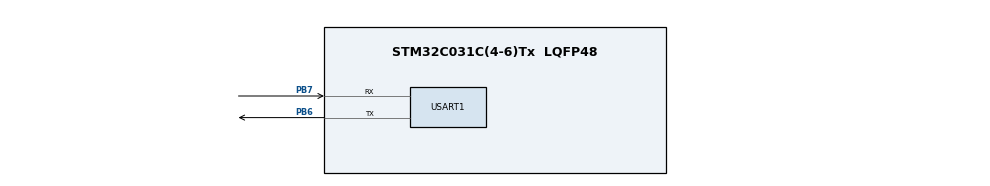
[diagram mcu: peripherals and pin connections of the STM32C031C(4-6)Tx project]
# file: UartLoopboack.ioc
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Mcu.Family=STM32C0
Mcu.Name=STM32C031C(4-6)Tx
Mcu.Package=LQFP48
PB6.Mode=Asynchronous
PB6.Signal=USART1_TX
PB7.Mode=Asynchronous
PB7.Signal=USART1_RX
ProjectManager.HeapSize=0x200
ProjectManager.StackSize=0x400
ProjectManager.TargetToolchain=STM32CubeIDE
RCC.ADCFreq_Value=12000000
RCC.AHBFreq_Value=12000000
RCC.CortexFreq_Value=12000000
RCC.EXTERNAL_CLOCK_VALUE=12288000
RCC.HCLKFreq_Value=12000000
RCC.HSE_VALUE=8000000
RCC.HSI_VALUE=48000000
RCC.LSE_VALUE=32768
RCC.SYSCLKFreq_VALUE=12000000
USART1.FIFOMode=FIFOMODE_ENABLE
USART1.VirtualMode-Asynchronous=VM_ASYNC
board=custom

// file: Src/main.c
/* USER CODE BEGIN Header */
/**
 ******************************************************************************
 * @file           : main.c
 * @brief          : Main program body
 ******************************************************************************
 * @attention
 *
 * Copyright (c) 2025 STMicroelectronics.
 * All rights reserved.
 *
 * This software is licensed under terms that can be found in the LICENSE file
 * in the root directory of this software component.
 * If no LICENSE file comes with this software, it is provided AS-IS.
 *
 ******************************************************************************
 */
/* USER CODE END Header */
#include "main.h"

/* USER CODE BEGIN Includes */
#include "byte_fifo.h"
/* USER CODE END Includes */

/* USER CODE BEGIN PM */
#define BUFFER_SIZE 256
/* USER CODE END PM */

UART_HandleTypeDef huart1;

/* USER CODE BEGIN PV */
static uint8_t fifo_data[BUFFER_SIZE];
static struct byte_fifo_t fifo =
    {
        .data = fifo_data,
        .size = BUFFER_SIZE,
};
/* USER CODE END PV */

void SystemClock_Config(void);
static void MX_GPIO_Init(void);
static void MX_USART1_UART_Init(void);

int main(void)
{

    /* MCU Configuration--------------------------------------------------------*/

    /* Reset of all peripherals, Initializes the Flash interface and the Systick. */
    HAL_Init();

    /* Configure the system clock */
    SystemClock_Config();

    /* Initialize all configured peripherals */
    MX_GPIO_Init();
    MX_USART1_UART_Init();
    /* USER CODE BEGIN 2 */

    byte_fifo_init(&fifo);

    /* USER CODE END 2 */

    /* Infinite loop */
    /* USER CODE BEGIN WHILE */
    while (1)
    {
        uint8_t tmp_byte;
        while (HAL_UART_Receive(&huart1, &tmp_byte, 1, 10) == HAL_OK)
        {
            byte_fifo_write(&fifo, &tmp_byte, 1);
        }

        while (byte_fifo_read(&fifo, &tmp_byte, 1) > 0)
        {
            HAL_UART_Transmit(&huart1, &tmp_byte, 1, HAL_MAX_DELAY);
        }
        /* USER CODE END WHILE */

    }
}

void SystemClock_Config(void)
{
    RCC_OscInitTypeDef RCC_OscInitStruct = {0};
    RCC_ClkInitTypeDef RCC_ClkInitStruct = {0};

    __HAL_FLASH_SET_LATENCY(FLASH_LATENCY_0);

    /** Initializes the RCC Oscillators according to the specified parameters
     * in the RCC_OscInitTypeDef structure.
     */
    RCC_OscInitStruct.OscillatorType = RCC_OSCILLATORTYPE_HSI;
    RCC_OscInitStruct.HSIState = RCC_HSI_ON;
    RCC_OscInitStruct.HSIDiv = RCC_HSI_DIV4;
    RCC_OscInitStruct.HSICalibrationValue = RCC_HSICALIBRATION_DEFAULT;
    if (HAL_RCC_OscConfig(&RCC_OscInitStruct) != HAL_OK)
    {
        Error_Handler();
    }

    /** Initializes the CPU, AHB and APB buses clocks
     */
    RCC_ClkInitStruct.ClockType = RCC_CLOCKTYPE_HCLK | RCC_CLOCKTYPE_SYSCLK | RCC_CLOCKTYPE_PCLK1;
    RCC_ClkInitStruct.SYSCLKSource = RCC_SYSCLKSOURCE_HSI;
    RCC_ClkInitStruct.SYSCLKDivider = RCC_SYSCLK_DIV1;
    RCC_ClkInitStruct.AHBCLKDivider = RCC_HCLK_DIV1;
    RCC_ClkInitStruct.APB1CLKDivider = RCC_APB1_DIV1;

    if (HAL_RCC_ClockConfig(&RCC_ClkInitStruct, FLASH_LATENCY_0) != HAL_OK)
    {
        Error_Handler();
    }
}

static void MX_USART1_UART_Init(void)
{

    huart1.Instance = USART1;
    huart1.Init.BaudRate = 115200;
    huart1.Init.WordLength = UART_WORDLENGTH_8B;
    huart1.Init.StopBits = UART_STOPBITS_1;
    huart1.Init.Parity = UART_PARITY_NONE;
    huart1.Init.Mode = UART_MODE_TX_RX;
    huart1.Init.HwFlowCtl = UART_HWCONTROL_NONE;
    huart1.Init.OverSampling = UART_OVERSAMPLING_16;
    huart1.Init.OneBitSampling = UART_ONE_BIT_SAMPLE_DISABLE;
    huart1.Init.ClockPrescaler = UART_PRESCALER_DIV1;
    huart1.AdvancedInit.AdvFeatureInit = UART_ADVFEATURE_NO_INIT;
    if (HAL_UART_Init(&huart1) != HAL_OK)
    {
        Error_Handler();
    }
    if (HAL_UARTEx_SetTxFifoThreshold(&huart1, UART_TXFIFO_THRESHOLD_1_8) != HAL_OK)
    {
        Error_Handler();
    }
    if (HAL_UARTEx_SetRxFifoThreshold(&huart1, UART_RXFIFO_THRESHOLD_1_8) != HAL_OK)
    {
        Error_Handler();
    }
    if (HAL_UARTEx_EnableFifoMode(&huart1) != HAL_OK)
    {
        Error_Handler();
    }
}

static void MX_GPIO_Init(void)
{

    /* GPIO Ports Clock Enable */
    __HAL_RCC_GPIOB_CLK_ENABLE();

}

void Error_Handler(void)
{
    __disable_irq();
    while (1)
    {
    }
}
